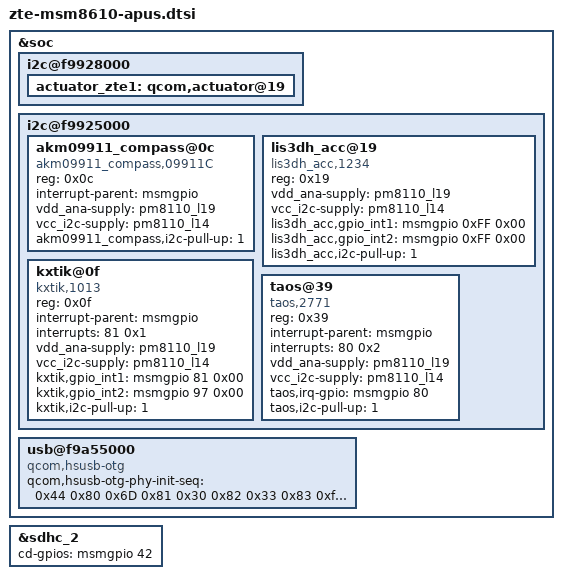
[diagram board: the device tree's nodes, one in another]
/* Copyright (c) 2013, The Linux Foundation. All rights reserved.
 *
 * This program is free software; you can redistribute it and/or modify
 * it under the terms of the GNU General Public License version 2 and
 * only version 2 as published by the Free Software Foundation.
 *
 * This program is distributed in the hope that it will be useful,
 * but WITHOUT ANY WARRANTY; without even the implied warranty of
 * MERCHANTABILITY or FITNESS FOR A PARTICULAR PURPOSE.  See the
 * GNU General Public License for more details.
 */


/include/ "touch-key-backlight-apus.dtsi"
/include/ "msm8610-camera-sensor-cdp-mtp.dtsi"

&soc {

	i2c@f9928000 {
		
		actuator_zte1: qcom,actuator@19 {
			status = "ok";
		};

	};
	
	i2c@f9925000 {
	
	    akm09911_compass@0c {
		    compatible = "akm09911_compass,09911C";
		    reg = <0x0c>;
		    interrupt-parent = <&msmgpio>;
		    //interrupts = <83 0x2>;	
		    vdd_ana-supply = <&pm8110_l19>;
		    vcc_i2c-supply = <&pm8110_l14>;
		    //akm09911_compass,gpio_int = <&msmgpio 83 0x00>;
		    akm09911_compass,i2c-pull-up = <1>;
           }; 
		
		lis3dh_acc@19 {
			compatible = "lis3dh_acc,1234";
			reg = <0x19>;
			vdd_ana-supply = <&pm8110_l19>;
			vcc_i2c-supply = <&pm8110_l14>;
			lis3dh_acc,gpio_int1 = <&msmgpio 0xFF 0x00>;
			lis3dh_acc,gpio_int2 = <&msmgpio 0xFF 0x00>;			
			lis3dh_acc,i2c-pull-up = <1>;
        	}; 

		kxtik@0f {
			compatible = "kxtik,1013";
			reg = <0x0f>;
			interrupt-parent = <&msmgpio>;
			interrupts = <81 0x1>;
			vdd_ana-supply = <&pm8110_l19>;
			vcc_i2c-supply = <&pm8110_l14>;
			kxtik,gpio_int1 = <&msmgpio 81 0x00>;
			kxtik,gpio_int2 = <&msmgpio 97 0x00>;			
			kxtik,i2c-pull-up = <1>;
        	}; 		
			
		taos@39 {
			compatible = "taos,2771";
			reg = <0x39>;
			interrupt-parent = <&msmgpio>;
			interrupts = <80 0x2>;
			vdd_ana-supply = <&pm8110_l19>;
			vcc_i2c-supply = <&pm8110_l14>;
			taos,irq-gpio = <&msmgpio 80 0x00>;
			taos,i2c-pull-up = <1>;
        	};
    };

    usb@f9a55000 {
	    compatible = "qcom,hsusb-otg";
	    qcom,hsusb-otg-phy-init-seq =
	    <0x44 0x80 0x6D 0x81 0x30 0x82 0x33 0x83 0xffffffff>;
    };
	
};

&sdhc_2 {
         cd-gpios = <&msmgpio 42 0x0>;
};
